# ATtiny841 register map
Vendor: Atmel
Registers are 8-bit, read-write, reset 0x0 unless marked. A register's access mark holds for its fields unless they carry their own. Offsets are from the block's base; [hi:lo] are bit positions; {n}, {i} and the like mark numbered series; 'fields as' and 'values as' point back to an identical list; <NAME> marks a mode.

## LOCKBIT — Lockbits
Base 0x00000000
0x00 LOCKBIT — <TBD>
  [1:0] LB — Memory Lock
    0=PROG_VER_DISABLED (Further programming and verification disabled); 2=PROG_DISABLED (Further programming disabled); 3=NO_LOCK (No memory lock features enabled)

## PORTA — I/O Port
Base 0x00000039
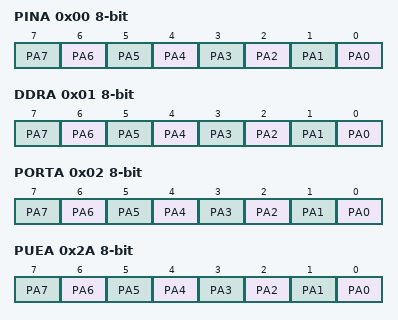
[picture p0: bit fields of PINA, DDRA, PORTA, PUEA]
0x00 PINA — Port A Input Pins
  [n] PA{n} (n=0..7) — Pin A{n}
0x01 DDRA — Data Direction Register, Port A
  [n] PA{n} (n=0..7) — Pin A{n}
0x02 PORTA — Port A Data Register
  [n] PA{n} (n=0..7) — Pin A{n}
0x2A PUEA — Pull-up Enable Control Register
  [n] PA{n} (n=0..7) — Pin A{n}
0x2B PORTCR — Port Control Register
  [0] BBMA — Break-Before-Make Mode Enable
0x31 PHDE — Port High Drive Enable Register
  [1:0] PHDEA — PortA High Drive Enable

## PORTB — I/O Port
Base 0x00000036
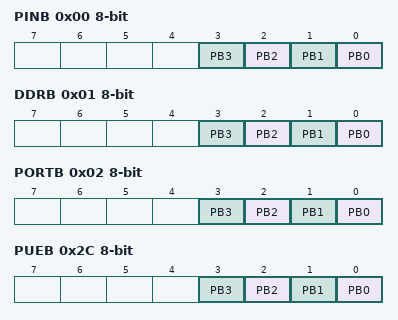
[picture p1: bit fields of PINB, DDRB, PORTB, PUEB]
0x00 PINB — Port B Data register
  [n] PB{n} (n=0..3) — Pin B{n}
0x01 DDRB — Data Direction Register, Port B
  [n] PB{n} (n=0..3) — Pin B{n}
0x02 PORTB — Input Pins, Port B
  [n] PB{n} (n=0..3) — Pin B{n}
0x2C PUEB — Pull-up Enable Control Register
  [n] PB{n} (n=0..3) — Pin B{n}
0x2E PORTCR — Port Control Register
  [1] BBMB — Break-Before-Make Mode Enable

## SPI — Serial Peripheral Interface
Base 0x00000065
0x00 REMAP — Remap Port Pins
  [1] SPIMAP — SPI Pin Mapping
0x4B SPDR — SPI Data Register
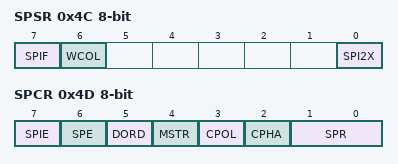
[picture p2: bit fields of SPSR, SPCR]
0x4C SPSR — SPI Status Register
  [7] SPIF ro — SPI Interrupt Flag
  [6] WCOL ro — Write Collision Flag
  [0] SPI2X — Double SPI Speed Bit
0x4D SPCR — SPI Control Register
  [7] SPIE — SPI Interrupt Enable
  [6] SPE — SPI Enable
  [5] DORD — Data Order
  [4] MSTR — Master/Slave Select
  [3] CPOL — Clock polarity
  [2] CPHA — Clock Phase
  [1:0] SPR — SPI Clock Rate Selects
    0=FOSC_4_2 (Fosc/4 if SPI2X == 0 else Fosc/2); 1=FOSC_16_8 (Fosc/16 if SPI2X == 0 else Fosc/8); 2=FOSC_64_32 (Fosc/64 if SPI2X == 0 else Fosc/32); 3=FOSC_128_64 (Fosc/128 if SPI2X == 0 else Fosc/64)

## TC0 — Timer/Counter0, 8-bit, PWM
Base 0x00000043
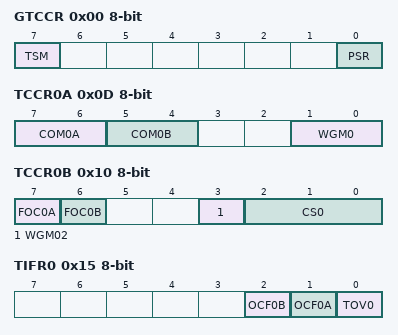
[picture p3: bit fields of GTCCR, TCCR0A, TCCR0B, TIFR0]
0x00 GTCCR — General Timer/Counter Control Register
  [7] TSM — Timer/Counter Synchronization Mode
  [0] PSR — Prescaler Reset Timer/CounterN
0x0D TCCR0A — Timer/Counter Control Register A
  [7:6] COM0A — Compare Output A Mode
    0=DISCONNECTED (Normal port operation, OCix disconnected); 1=MATCH_TOGGLE (Toggle OCix on Compare Match (Might depend on WGM)); 2=MATCH_CLEAR (Clear OCix on Compare Match (If PWM is enabled, OCix is set at BOTTOM)); 3=MATCH_SET (Set OCix on Compare Match (If PWM is enabled, OCix is cleared at BOTTOM))
  [5:4] COM0B — Compare Output B Mode
    values as COM0A
  [1:0] WGM0 — Waveform Generation Mode bits
    0=NORMAL_TOP (Normal, Top: `0xff`, Update: *Immediate*, Flag: *MAX*); 1=PWM_PHASE (Phase Correct PWM, Top: `0xff`, Update: *TOP*, Flag: *BOTTOM*); 2=CTC (CTC, Top: *OCRA*, Update: *Immediate*, Flag: *MAX*); 3=PWM_FAST (Fast PWM, Top: `0xff`, Update: *BOTTOM*, Flag: *TOP*)
0x0F TCNT0 — Timer/Counter0
0x10 TCCR0B — Timer/Counter Control Register B
  [7] FOC0A wo — Force Output Compare A
  [6] FOC0B wo — Force Output Compare B
  [3] WGM02 — Waveform Generation Mode High Bit (Enable Top: *OCRA* for `PWM` modes)
  [2:0] CS0 — Clock Select bits
    0=NO_CLOCK (No clock source (Timer/Counter stopped)); 1=DIRECT (Running, No Prescaling); 2=PRESCALE_8 (Running, CLK/8); 3=PRESCALE_64 (Running, CLK/64); 4=PRESCALE_256 (Running, CLK/256); 5=PRESCALE_1024 (Running, CLK/1024); 6=EXT_FALLING (Running, ExtClk Tx Falling Edge); 7=EXT_RISING (Running, ExtClk Tx Rising Edge)
0x13 OCR0A — Output Compare Register A
0x15 TIFR0 ro — Timer/Counter0 Interrupt Flag Register
  [2] OCF0B — Timer/Counter0 Output Compare Flag B
  [1] OCF0A — Timer/Counter0 Output Compare Flag A
  [0] TOV0 — Timer/Counter0 Overflow Flag
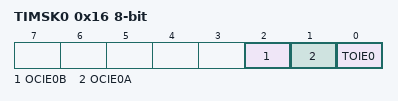
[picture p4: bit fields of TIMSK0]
0x16 TIMSK0 — Timer/Counter Interrupt Mask Register
  [2] OCIE0B — Timer/Counter0 Output Compare Match B Interrupt Enable
  [1] OCIE0A — Timer/Counter0 Output Compare Match A Interrupt Enable
  [0] TOIE0 — Timer/Counter0 Overflow Interrupt Enable
0x19 OCR0B — Output Compare Register B
